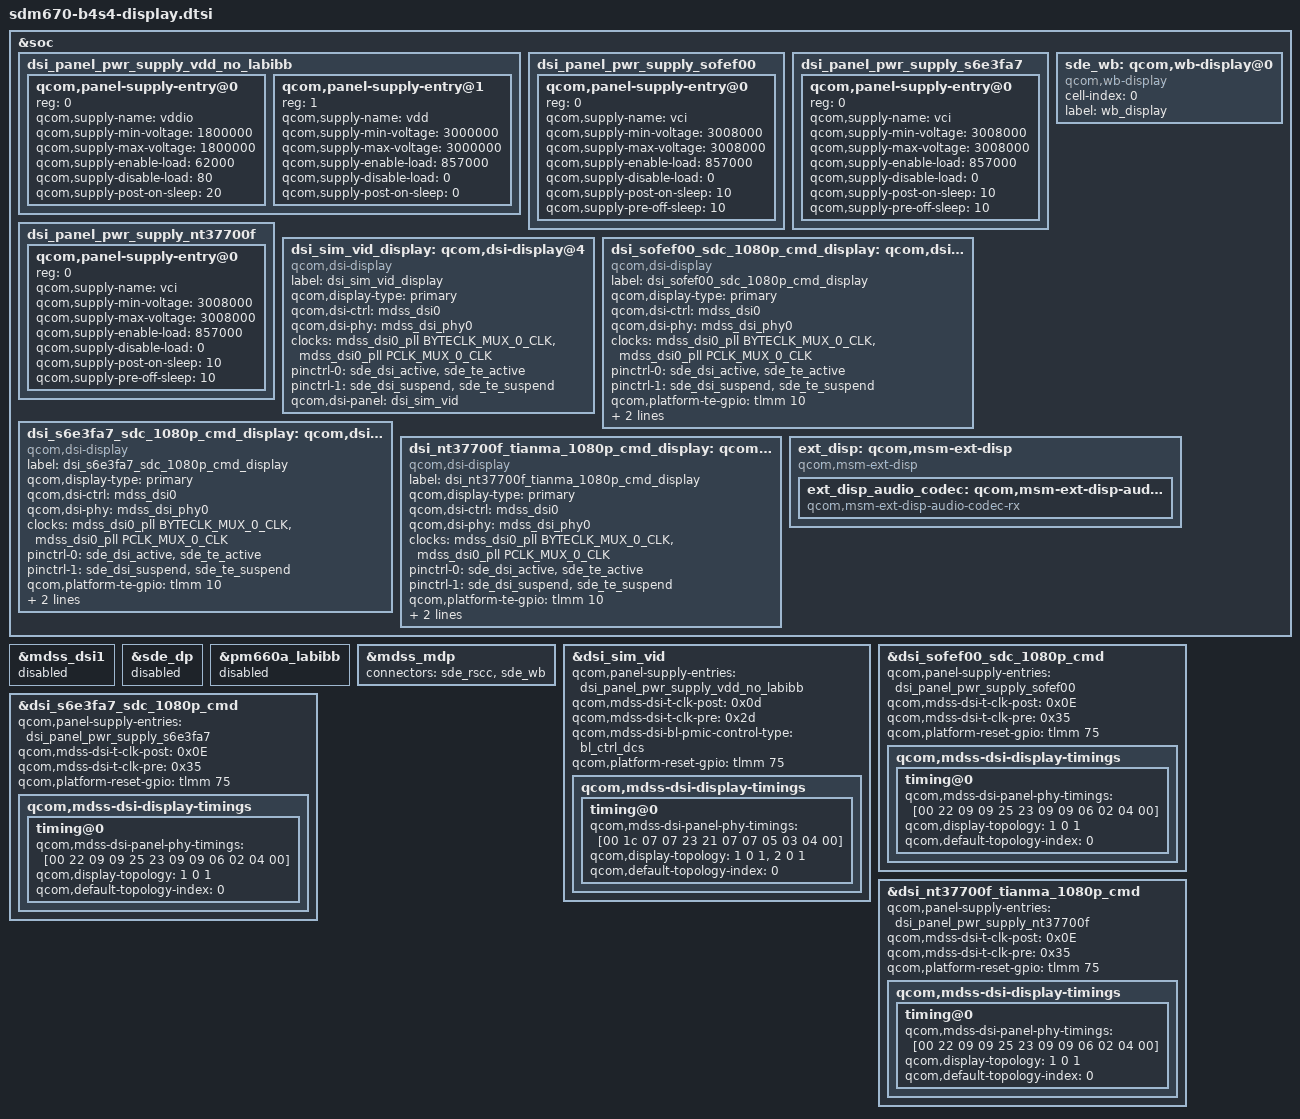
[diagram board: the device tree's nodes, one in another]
/* Copyright (c) 2017-2018, The Linux Foundation. All rights reserved.
 *
 * This program is free software; you can redistribute it and/or modify
 * it under the terms of the GNU General Public License version 2 and
 * only version 2 as published by the Free Software Foundation.
 *
 * This program is distributed in the hope that it will be useful,
 * but WITHOUT ANY WARRANTY; without even the implied warranty of
 * MERCHANTABILITY or FITNESS FOR A PARTICULAR PURPOSE.  See the
 * GNU General Public License for more details.
 */

#include "../qcom/dsi-panel-sim-video.dtsi"
#include "dsi-panel-sofef00-1080p-cmd.dtsi"
#include "dsi-panel-s6e3fa7-1080p-cmd.dtsi"
#include "dsi-panel-nt37700f-1080p-cmd.dtsi"
#include <dt-bindings/clock/mdss-10nm-pll-clk.h>

&soc {
	dsi_panel_pwr_supply_vdd_no_labibb: dsi_panel_pwr_supply_vdd_no_labibb {
		#address-cells = <1>;
		#size-cells = <0>;

		qcom,panel-supply-entry@0 {
			reg = <0>;
			qcom,supply-name = "vddio";
			qcom,supply-min-voltage = <1800000>;
			qcom,supply-max-voltage = <1800000>;
			qcom,supply-enable-load = <62000>;
			qcom,supply-disable-load = <80>;
			qcom,supply-post-on-sleep = <20>;
		};

		qcom,panel-supply-entry@1 {
			reg = <1>;
			qcom,supply-name = "vdd";
			qcom,supply-min-voltage = <3000000>;
			qcom,supply-max-voltage = <3000000>;
			qcom,supply-enable-load = <857000>;
			qcom,supply-disable-load = <0>;
			qcom,supply-post-on-sleep = <0>;
		};
	};

	dsi_panel_pwr_supply_sofef00: dsi_panel_pwr_supply_sofef00 {
		#address-cells = <1>;
		#size-cells = <0>;

		qcom,panel-supply-entry@0 {
			reg = <0>;
			qcom,supply-name = "vci";
			qcom,supply-min-voltage = <3008000>;
			qcom,supply-max-voltage = <3008000>;
			qcom,supply-enable-load = <857000>;
			qcom,supply-disable-load = <0>;
			qcom,supply-post-on-sleep = <10>;
			qcom,supply-pre-off-sleep = <10>;
		};
	};

	dsi_panel_pwr_supply_s6e3fa7: dsi_panel_pwr_supply_s6e3fa7 {
		#address-cells = <1>;
		#size-cells = <0>;

		qcom,panel-supply-entry@0 {
			reg = <0>;
			qcom,supply-name = "vci";
			qcom,supply-min-voltage = <3008000>;
			qcom,supply-max-voltage = <3008000>;
			qcom,supply-enable-load = <857000>;
			qcom,supply-disable-load = <0>;
			qcom,supply-post-on-sleep = <10>;
			qcom,supply-pre-off-sleep = <10>;
		};
	};

	dsi_panel_pwr_supply_nt37700f: dsi_panel_pwr_supply_nt37700f {
		#address-cells = <1>;
		#size-cells = <0>;

		qcom,panel-supply-entry@0 {
			reg = <0>;
			qcom,supply-name = "vci";
			qcom,supply-min-voltage = <3008000>;
			qcom,supply-max-voltage = <3008000>;
			qcom,supply-enable-load = <857000>;
			qcom,supply-disable-load = <0>;
			qcom,supply-post-on-sleep = <10>;
			qcom,supply-pre-off-sleep = <10>;
		};
	};

	dsi_sim_vid_display: qcom,dsi-display@4 {
		compatible = "qcom,dsi-display";
		label = "dsi_sim_vid_display";
		qcom,display-type = "primary";

		qcom,dsi-ctrl = <&mdss_dsi0>;
		qcom,dsi-phy = <&mdss_dsi_phy0>;
		clocks = <&mdss_dsi0_pll BYTECLK_MUX_0_CLK>,
			 <&mdss_dsi0_pll PCLK_MUX_0_CLK>;
		clock-names = "src_byte_clk", "src_pixel_clk";

		pinctrl-names = "panel_active", "panel_suspend";
		pinctrl-0 = <&sde_dsi_active &sde_te_active>;
		pinctrl-1 = <&sde_dsi_suspend &sde_te_suspend>;

		qcom,dsi-panel = <&dsi_sim_vid>;
	};

	dsi_sofef00_sdc_1080p_cmd_display: qcom,dsi-display@50 {
		compatible = "qcom,dsi-display";
		label = "dsi_sofef00_sdc_1080p_cmd_display";
		qcom,display-type = "primary";

		qcom,dsi-ctrl = <&mdss_dsi0>;
		qcom,dsi-phy = <&mdss_dsi_phy0>;
		clocks = <&mdss_dsi0_pll BYTECLK_MUX_0_CLK>,
			 <&mdss_dsi0_pll PCLK_MUX_0_CLK>;
		clock-names = "src_byte_clk", "src_pixel_clk";

		pinctrl-names = "panel_active", "panel_suspend";
		pinctrl-0 = <&sde_dsi_active &sde_te_active>;
		pinctrl-1 = <&sde_dsi_suspend &sde_te_suspend>;
		qcom,platform-te-gpio = <&tlmm 10 0>;

		qcom,dsi-panel = <&dsi_sofef00_sdc_1080p_cmd>;
		vci-supply = <&pm660l_l6>; /* 3008mV */
	};

	dsi_s6e3fa7_sdc_1080p_cmd_display: qcom,dsi-display@51 {
		compatible = "qcom,dsi-display";
		label = "dsi_s6e3fa7_sdc_1080p_cmd_display";
		qcom,display-type = "primary";

		qcom,dsi-ctrl = <&mdss_dsi0>;
		qcom,dsi-phy = <&mdss_dsi_phy0>;
		clocks = <&mdss_dsi0_pll BYTECLK_MUX_0_CLK>,
			 <&mdss_dsi0_pll PCLK_MUX_0_CLK>;
		clock-names = "src_byte_clk", "src_pixel_clk";

		pinctrl-names = "panel_active", "panel_suspend";
		pinctrl-0 = <&sde_dsi_active &sde_te_active>;
		pinctrl-1 = <&sde_dsi_suspend &sde_te_suspend>;
		qcom,platform-te-gpio = <&tlmm 10 0>;

		qcom,dsi-panel = <&dsi_s6e3fa7_sdc_1080p_cmd>;
		vci-supply = <&pm660l_l6>; /* 3008mV */
	};

	dsi_nt37700f_tianma_1080p_cmd_display: qcom,dsi-display@52 {
		compatible = "qcom,dsi-display";
		label = "dsi_nt37700f_tianma_1080p_cmd_display";
		qcom,display-type = "primary";

		qcom,dsi-ctrl = <&mdss_dsi0>;
		qcom,dsi-phy = <&mdss_dsi_phy0>;
		clocks = <&mdss_dsi0_pll BYTECLK_MUX_0_CLK>,
			 <&mdss_dsi0_pll PCLK_MUX_0_CLK>;
		clock-names = "src_byte_clk", "src_pixel_clk";

		pinctrl-names = "panel_active", "panel_suspend";
		pinctrl-0 = <&sde_dsi_active &sde_te_active>;
		pinctrl-1 = <&sde_dsi_suspend &sde_te_suspend>;
		qcom,platform-te-gpio = <&tlmm 10 0>;

		qcom,dsi-panel = <&dsi_nt37700f_tianma_1080p_cmd>;
		vci-supply = <&pm660l_l6>; /* 3008mV */
	};

	sde_wb: qcom,wb-display@0 {
		compatible = "qcom,wb-display";
		cell-index = <0>;
		label = "wb_display";
	};

	ext_disp: qcom,msm-ext-disp {
		compatible = "qcom,msm-ext-disp";

		ext_disp_audio_codec: qcom,msm-ext-disp-audio-codec-rx {
			compatible = "qcom,msm-ext-disp-audio-codec-rx";
		};
	};
};

&mdss_dsi1 {
	status = "disabled";
};

&sde_dp {
	status = "disabled";
};

&pm660a_labibb {
	status = "disabled";
};

&mdss_mdp {
	connectors = <&sde_rscc &sde_wb>;
};

&dsi_sim_vid {
	qcom,panel-supply-entries = <&dsi_panel_pwr_supply_vdd_no_labibb>;
	qcom,mdss-dsi-t-clk-post = <0x0d>;
	qcom,mdss-dsi-t-clk-pre = <0x2d>;
	qcom,mdss-dsi-bl-pmic-control-type = "bl_ctrl_dcs";

	qcom,platform-reset-gpio = <&tlmm 75 0>;
	qcom,mdss-dsi-display-timings {
		timing@0{
			qcom,mdss-dsi-panel-phy-timings = [00 1c 07 07 23 21 07
				07 05 03 04 00];
			qcom,display-topology = <1 0 1>,
						<2 0 1>;
			qcom,default-topology-index = <0>;
		};
	};
};

&dsi_sofef00_sdc_1080p_cmd {
	qcom,panel-supply-entries = <&dsi_panel_pwr_supply_sofef00>;
	qcom,mdss-dsi-t-clk-post = <0x0E>;
	qcom,mdss-dsi-t-clk-pre = <0x35>;

	qcom,platform-reset-gpio = <&tlmm 75 0>;
	qcom,mdss-dsi-display-timings {
		timing@0 {
			qcom,mdss-dsi-panel-phy-timings =
					[00 22 09 09 25 23 09 09 06 02 04 00];
			qcom,display-topology = <1 0 1>;
			qcom,default-topology-index = <0>;
		};
	};
};

&dsi_s6e3fa7_sdc_1080p_cmd {
	qcom,panel-supply-entries = <&dsi_panel_pwr_supply_s6e3fa7>;
	qcom,mdss-dsi-t-clk-post = <0x0E>;
	qcom,mdss-dsi-t-clk-pre = <0x35>;

	qcom,platform-reset-gpio = <&tlmm 75 0>;
	qcom,mdss-dsi-display-timings {
		timing@0 {
			qcom,mdss-dsi-panel-phy-timings =
					[00 22 09 09 25 23 09 09 06 02 04 00];
			qcom,display-topology = <1 0 1>;
			qcom,default-topology-index = <0>;
		};
	};
};

&dsi_nt37700f_tianma_1080p_cmd {
	qcom,panel-supply-entries = <&dsi_panel_pwr_supply_nt37700f>;
	qcom,mdss-dsi-t-clk-post = <0x0E>;
	qcom,mdss-dsi-t-clk-pre = <0x35>;

	qcom,platform-reset-gpio = <&tlmm 75 0>;
	qcom,mdss-dsi-display-timings {
		timing@0 {
			qcom,mdss-dsi-panel-phy-timings =
					[00 22 09 09 25 23 09 09 06 02 04 00];
			qcom,display-topology = <1 0 1>;
			qcom,default-topology-index = <0>;
		};
	};
};
